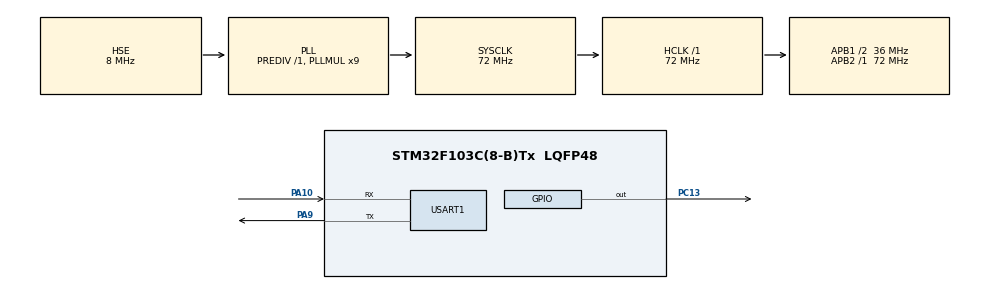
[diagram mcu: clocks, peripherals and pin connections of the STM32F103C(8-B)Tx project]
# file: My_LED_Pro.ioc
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FREERTOS.Tasks01=defaultTask,40,128,StartDefaultTask,Default,NULL,Dynamic,NULL,NULL;mylogTask,8,128,StartTask02,Default,NULL,Dynamic,NULL,NULL;myTask03,9,128,cpu_load,Default,NULL,Dynamic,NULL,NULL
FREERTOS.configGENERATE_RUN_TIME_STATS=1
FREERTOS.configUSE_IDLE_HOOK=1
FREERTOS.configUSE_STATS_FORMATTING_FUNCTIONS=1
Mcu.Family=STM32F1
Mcu.Name=STM32F103C(8-B)Tx
Mcu.Package=LQFP48
Mcu.UserConstants=UART,1
NVIC.PriorityGroup=NVIC_PRIORITYGROUP_4
NVIC.TIM2_IRQn=true\:5\:0\:false\:false\:true\:true\:true\:true\:true
NVIC.TIM3_IRQn=true\:5\:0\:true\:false\:true\:true\:true\:true\:true
PA10.Mode=Asynchronous
PA10.Signal=USART1_RX
PA13.Mode=Serial_Wire
PA13.Signal=SYS_JTMS-SWDIO
PA14.Mode=Serial_Wire
PA14.Signal=SYS_JTCK-SWCLK
PA9.Mode=Asynchronous
PA9.Signal=USART1_TX
PC13-TAMPER-RTC.Signal=GPIO_Output
PD0-OSC_IN.Mode=HSE-External-Oscillator
PD0-OSC_IN.Signal=RCC_OSC_IN
PD1-OSC_OUT.Mode=HSE-External-Oscillator
PD1-OSC_OUT.Signal=RCC_OSC_OUT
ProjectManager.HeapSize=0x200
ProjectManager.StackSize=0x400
ProjectManager.TargetToolchain=MDK-ARM V5
RCC.AHBFreq_Value=72000000
RCC.APB1CLKDivider=RCC_HCLK_DIV2
RCC.APB1Freq_Value=36000000
RCC.APB1TimFreq_Value=72000000
RCC.APB2Freq_Value=72000000
RCC.APB2TimFreq_Value=72000000
RCC.HCLKFreq_Value=72000000
RCC.PLLMUL=RCC_PLL_MUL9
RCC.PLLSourceVirtual=RCC_PLLSOURCE_HSE
RCC.SYSCLKFreq_VALUE=72000000
RCC.SYSCLKSource=RCC_SYSCLKSOURCE_PLLCLK
RCC.USBFreq_Value=72000000
TIM2.AutoReloadPreload=TIM_AUTORELOAD_PRELOAD_ENABLE
TIM2.Period=50-1
TIM2.Prescaler=72-1
TIM3.AutoReloadPreload=TIM_AUTORELOAD_PRELOAD_ENABLE
TIM3.Period=1000-1
TIM3.Prescaler=72-1
USART1.VirtualMode=VM_ASYNC
VP_FREERTOS_VS_CMSIS_V2.Mode=CMSIS_V2
VP_TIM1_VS_ClockSourceITR.Mode=TriggerSource_ITR0
VP_TIM1_VS_ControllerModeTrigger.Mode=Trigger Mode
VP_TIM2_VS_ClockSourceINT.Mode=Internal
VP_TIM3_VS_ClockSourceINT.Mode=Internal
board=custom

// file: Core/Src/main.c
/* USER CODE BEGIN Header */
/**
  ******************************************************************************
  * @file           : main.c
  * @brief          : Main program body
  ******************************************************************************
  * @attention
  *
  * Copyright (c) 2023 STMicroelectronics.
  * All rights reserved.
  *
  * This software is licensed under terms that can be found in the LICENSE file
  * in the root directory of this software component.
  * If no LICENSE file comes with this software, it is provided AS-IS.
  *
  ******************************************************************************
  */
/* USER CODE END Header */
#include "main.h"
#include "cmsis_os.h"

 TIM_HandleTypeDef htim1;
TIM_HandleTypeDef htim2;
TIM_HandleTypeDef htim3;

UART_HandleTypeDef huart1;

/* Definitions for defaultTask */
osThreadId_t defaultTaskHandle;
const osThreadAttr_t defaultTask_attributes = {
  .name = "defaultTask",
  .stack_size = 128 * 4,
  .priority = (osPriority_t) osPriorityHigh,
};
/* Definitions for mylogTask */
osThreadId_t mylogTaskHandle;
const osThreadAttr_t mylogTask_attributes = {
  .name = "mylogTask",
  .stack_size = 128 * 4,
  .priority = (osPriority_t) osPriorityLow,
};
/* Definitions for myTask03 */
osThreadId_t myTask03Handle;
const osThreadAttr_t myTask03_attributes = {
  .name = "myTask03",
  .stack_size = 128 * 4,
  .priority = (osPriority_t) osPriorityLow1,
};

void SystemClock_Config(void);
static void MX_GPIO_Init(void);
static void MX_TIM1_Init(void);
static void MX_USART1_UART_Init(void);
static void MX_TIM3_Init(void);
static void MX_TIM2_Init(void);
void StartDefaultTask(void *argument);
void StartTask02(void *argument);
void cpu_load(void *argument);

/* USER CODE BEGIN 0 */
volatile uint32_t timer1_loop = 0;
volatile long timer_50us = 0;
/* USER CODE END 0 */

int main(void)
{

  /* MCU Configuration--------------------------------------------------------*/

  /* Reset of all peripherals, Initializes the Flash interface and the Systick. */
  HAL_Init();

  /* Configure the system clock */
  SystemClock_Config();

  /* Initialize all configured peripherals */
  MX_GPIO_Init();
  MX_TIM1_Init();
  MX_USART1_UART_Init();
  MX_TIM3_Init();
  MX_TIM2_Init();

  /* Init scheduler */
  osKernelInitialize();

  /* Create the thread(s) */
  /* creation of defaultTask */
  defaultTaskHandle = osThreadNew(StartDefaultTask, NULL, &defaultTask_attributes);

  /* creation of mylogTask */
  mylogTaskHandle = osThreadNew(StartTask02, NULL, &mylogTask_attributes);

  /* creation of myTask03 */
  myTask03Handle = osThreadNew(cpu_load, NULL, &myTask03_attributes);

  /* USER CODE BEGIN RTOS_EVENTS */
	//HAL_TIM_Base_Start_IT(&htim1);
	HAL_TIM_Base_Start_IT(&htim3);
	HAL_TIM_Base_Start_IT(&htim2);

	uart_printf_init(&huart1);
  /* USER CODE END RTOS_EVENTS */

  /* Start scheduler */
  osKernelStart();

  /* We should never get here as control is now taken by the scheduler */
  /* Infinite loop */
  while (1)
  {

  }
}

void SystemClock_Config(void)
{
  RCC_OscInitTypeDef RCC_OscInitStruct = {0};
  RCC_ClkInitTypeDef RCC_ClkInitStruct = {0};

  /** Initializes the RCC Oscillators according to the specified parameters
  * in the RCC_OscInitTypeDef structure.
  */
  RCC_OscInitStruct.OscillatorType = RCC_OSCILLATORTYPE_HSE;
  RCC_OscInitStruct.HSEState = RCC_HSE_ON;
  RCC_OscInitStruct.HSEPredivValue = RCC_HSE_PREDIV_DIV1;
  RCC_OscInitStruct.HSIState = RCC_HSI_ON;
  RCC_OscInitStruct.PLL.PLLState = RCC_PLL_ON;
  RCC_OscInitStruct.PLL.PLLSource = RCC_PLLSOURCE_HSE;
  RCC_OscInitStruct.PLL.PLLMUL = RCC_PLL_MUL9;
  if (HAL_RCC_OscConfig(&RCC_OscInitStruct) != HAL_OK)
  {
    Error_Handler();
  }

  /** Initializes the CPU, AHB and APB buses clocks
  */
  RCC_ClkInitStruct.ClockType = RCC_CLOCKTYPE_HCLK|RCC_CLOCKTYPE_SYSCLK
                              |RCC_CLOCKTYPE_PCLK1|RCC_CLOCKTYPE_PCLK2;
  RCC_ClkInitStruct.SYSCLKSource = RCC_SYSCLKSOURCE_PLLCLK;
  RCC_ClkInitStruct.AHBCLKDivider = RCC_SYSCLK_DIV1;
  RCC_ClkInitStruct.APB1CLKDivider = RCC_HCLK_DIV2;
  RCC_ClkInitStruct.APB2CLKDivider = RCC_HCLK_DIV1;

  if (HAL_RCC_ClockConfig(&RCC_ClkInitStruct, FLASH_LATENCY_2) != HAL_OK)
  {
    Error_Handler();
  }
}

static void MX_TIM1_Init(void)
{

  TIM_SlaveConfigTypeDef sSlaveConfig = {0};
  TIM_MasterConfigTypeDef sMasterConfig = {0};

  htim1.Instance = TIM1;
  htim1.Init.Prescaler = 0;
  htim1.Init.CounterMode = TIM_COUNTERMODE_UP;
  htim1.Init.Period = 65535;
  htim1.Init.ClockDivision = TIM_CLOCKDIVISION_DIV1;
  htim1.Init.RepetitionCounter = 0;
  htim1.Init.AutoReloadPreload = TIM_AUTORELOAD_PRELOAD_DISABLE;
  if (HAL_TIM_Base_Init(&htim1) != HAL_OK)
  {
    Error_Handler();
  }
  sSlaveConfig.SlaveMode = TIM_SLAVEMODE_TRIGGER;
  sSlaveConfig.InputTrigger = TIM_TS_ITR0;
  if (HAL_TIM_SlaveConfigSynchro(&htim1, &sSlaveConfig) != HAL_OK)
  {
    Error_Handler();
  }
  sMasterConfig.MasterOutputTrigger = TIM_TRGO_RESET;
  sMasterConfig.MasterSlaveMode = TIM_MASTERSLAVEMODE_DISABLE;
  if (HAL_TIMEx_MasterConfigSynchronization(&htim1, &sMasterConfig) != HAL_OK)
  {
    Error_Handler();
  }

}

static void MX_TIM2_Init(void)
{

  TIM_ClockConfigTypeDef sClockSourceConfig = {0};
  TIM_MasterConfigTypeDef sMasterConfig = {0};

  htim2.Instance = TIM2;
  htim2.Init.Prescaler = 72-1;
  htim2.Init.CounterMode = TIM_COUNTERMODE_UP;
  htim2.Init.Period = 50-1;
  htim2.Init.ClockDivision = TIM_CLOCKDIVISION_DIV1;
  htim2.Init.AutoReloadPreload = TIM_AUTORELOAD_PRELOAD_ENABLE;
  if (HAL_TIM_Base_Init(&htim2) != HAL_OK)
  {
    Error_Handler();
  }
  sClockSourceConfig.ClockSource = TIM_CLOCKSOURCE_INTERNAL;
  if (HAL_TIM_ConfigClockSource(&htim2, &sClockSourceConfig) != HAL_OK)
  {
    Error_Handler();
  }
  sMasterConfig.MasterOutputTrigger = TIM_TRGO_RESET;
  sMasterConfig.MasterSlaveMode = TIM_MASTERSLAVEMODE_DISABLE;
  if (HAL_TIMEx_MasterConfigSynchronization(&htim2, &sMasterConfig) != HAL_OK)
  {
    Error_Handler();
  }

}

static void MX_TIM3_Init(void)
{

  TIM_ClockConfigTypeDef sClockSourceConfig = {0};
  TIM_MasterConfigTypeDef sMasterConfig = {0};

  htim3.Instance = TIM3;
  htim3.Init.Prescaler = 72-1;
  htim3.Init.CounterMode = TIM_COUNTERMODE_UP;
  htim3.Init.Period = 1000-1;
  htim3.Init.ClockDivision = TIM_CLOCKDIVISION_DIV1;
  htim3.Init.AutoReloadPreload = TIM_AUTORELOAD_PRELOAD_ENABLE;
  if (HAL_TIM_Base_Init(&htim3) != HAL_OK)
  {
    Error_Handler();
  }
  sClockSourceConfig.ClockSource = TIM_CLOCKSOURCE_INTERNAL;
  if (HAL_TIM_ConfigClockSource(&htim3, &sClockSourceConfig) != HAL_OK)
  {
    Error_Handler();
  }
  sMasterConfig.MasterOutputTrigger = TIM_TRGO_RESET;
  sMasterConfig.MasterSlaveMode = TIM_MASTERSLAVEMODE_DISABLE;
  if (HAL_TIMEx_MasterConfigSynchronization(&htim3, &sMasterConfig) != HAL_OK)
  {
    Error_Handler();
  }

}

static void MX_USART1_UART_Init(void)
{

  huart1.Instance = USART1;
  huart1.Init.BaudRate = 115200;
  huart1.Init.WordLength = UART_WORDLENGTH_8B;
  huart1.Init.StopBits = UART_STOPBITS_1;
  huart1.Init.Parity = UART_PARITY_NONE;
  huart1.Init.Mode = UART_MODE_TX_RX;
  huart1.Init.HwFlowCtl = UART_HWCONTROL_NONE;
  huart1.Init.OverSampling = UART_OVERSAMPLING_16;
  if (HAL_UART_Init(&huart1) != HAL_OK)
  {
    Error_Handler();
  }

}

static void MX_GPIO_Init(void)
{
  GPIO_InitTypeDef GPIO_InitStruct = {0};

  /* GPIO Ports Clock Enable */
  __HAL_RCC_GPIOC_CLK_ENABLE();
  __HAL_RCC_GPIOD_CLK_ENABLE();
  __HAL_RCC_GPIOA_CLK_ENABLE();

  /*Configure GPIO pin Output Level */
  HAL_GPIO_WritePin(GPIOC, GPIO_PIN_13, GPIO_PIN_RESET);

  /*Configure GPIO pin : PC13 */
  GPIO_InitStruct.Pin = GPIO_PIN_13;
  GPIO_InitStruct.Mode = GPIO_MODE_OUTPUT_PP;
  GPIO_InitStruct.Pull = GPIO_NOPULL;
  GPIO_InitStruct.Speed = GPIO_SPEED_FREQ_LOW;
  HAL_GPIO_Init(GPIOC, &GPIO_InitStruct);

}

/* USER CODE BEGIN 4 */
unsigned long getRunTimeCounterValue(void)
{
    return timer_50us;
}

void HAL_TIM_PeriodElapsedCallback(TIM_HandleTypeDef *htim)
{
  if(htim->Instance == TIM1)
  {
   // timer1_loop++;
  }
  else if(htim->Instance == TIM3)
  {
    timer1_loop++;
  }
  else if(htim->Instance == TIM2)
  {
    timer_50us++;
  }
}
/* USER CODE END 4 */

void StartDefaultTask(void *argument)
{
  /* USER CODE BEGIN 5 */

  /* Infinite loop */
  for(;;)
  {

    int a=0;
    uint32_t timer = timer1_loop;
    for(uint32_t i=0; i< 0xFFF;i++)
    {
      for(uint32_t j=0;j<0xFF;j++)
      {
        a+=j;
      }
    }
    UART_printf("caculator  = %08x time cost %d\r\n",a,timer1_loop-timer);
		osDelay(100);
  }
  /* USER CODE END 5 */
}

void StartTask02(void *argument)
{
  /* USER CODE BEGIN StartTask02 */
  /* Infinite loop */
  for(;;)
  {
    log_buffer_flush();
    osDelay(500);
  }
  /* USER CODE END StartTask02 */
}

void cpu_load(void *argument)
{
  /* USER CODE BEGIN cpu_load */
  uint32_t time =0;
  uint8_t cpu_info[256];
	uint8_t pin = GPIO_PIN_SET;
  /* Infinite loop */
  for(;;)
  {
    UART_printf("timer2 %d\r\n",timer_50us);
		UART_printf("hello world %d\r\n",timer1_loop-time);
		time = timer1_loop;
		HAL_GPIO_WritePin(GPIOC,GPIO_PIN_13,pin);
    pin = !pin;
    memset(&cpu_info,0,sizeof(cpu_info));
    // UART_printf("#######cpuinfo########\r\n");
    // // vTaskList(&cpu_info);
    // // UART_printf("%s",cpu_info);
    UART_printf("#######cpuload########\r\n");
    memset(&cpu_info,0,sizeof(cpu_info));
    vTaskGetRunTimeStats(&cpu_info);
    UART_printf("%s",cpu_info);

    osDelay(1000);
  }
  /* USER CODE END cpu_load */
}

void Error_Handler(void)
{
  __disable_irq();
  while (1)
  {
  }
}

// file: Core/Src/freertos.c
/* USER CODE BEGIN Header */
/**
  ******************************************************************************
  * File Name          : freertos.c
  * Description        : Code for freertos applications
  ******************************************************************************
  * @attention
  *
  * Copyright (c) 2023 STMicroelectronics.
  * All rights reserved.
  *
  * This software is licensed under terms that can be found in the LICENSE file
  * in the root directory of this software component.
  * If no LICENSE file comes with this software, it is provided AS-IS.
  *
  ******************************************************************************
  */
/* USER CODE END Header */

#include "FreeRTOS.h"
#include "task.h"
#include "main.h"

/* Hook prototypes */
void configureTimerForRunTimeStats(void);
unsigned long getRunTimeCounterValue(void);
void vApplicationIdleHook(void);

/* USER CODE BEGIN 1 */
/* Functions needed when configGENERATE_RUN_TIME_STATS is on */
__weak void configureTimerForRunTimeStats(void)
{

}

__weak unsigned long getRunTimeCounterValue(void)
{
return 0;
}
/* USER CODE END 1 */

/* USER CODE BEGIN 2 */
void vApplicationIdleHook( void )
{
   /* vApplicationIdleHook() will only be called if configUSE_IDLE_HOOK is set
   to 1 in FreeRTOSConfig.h. It will be called on each iteration of the idle
   task. It is essential that code added to this hook function never attempts
   to block in any way (for example, call xQueueReceive() with a block time
   specified, or call vTaskDelay()). If the application makes use of the
   vTaskDelete() API function (as this demo application does) then it is also
   important that vApplicationIdleHook() is permitted to return to its calling
   function, because it is the responsibility of the idle task to clean up
   memory allocated by the kernel to any task that has since been deleted. */
}
/* USER CODE END 2 */
